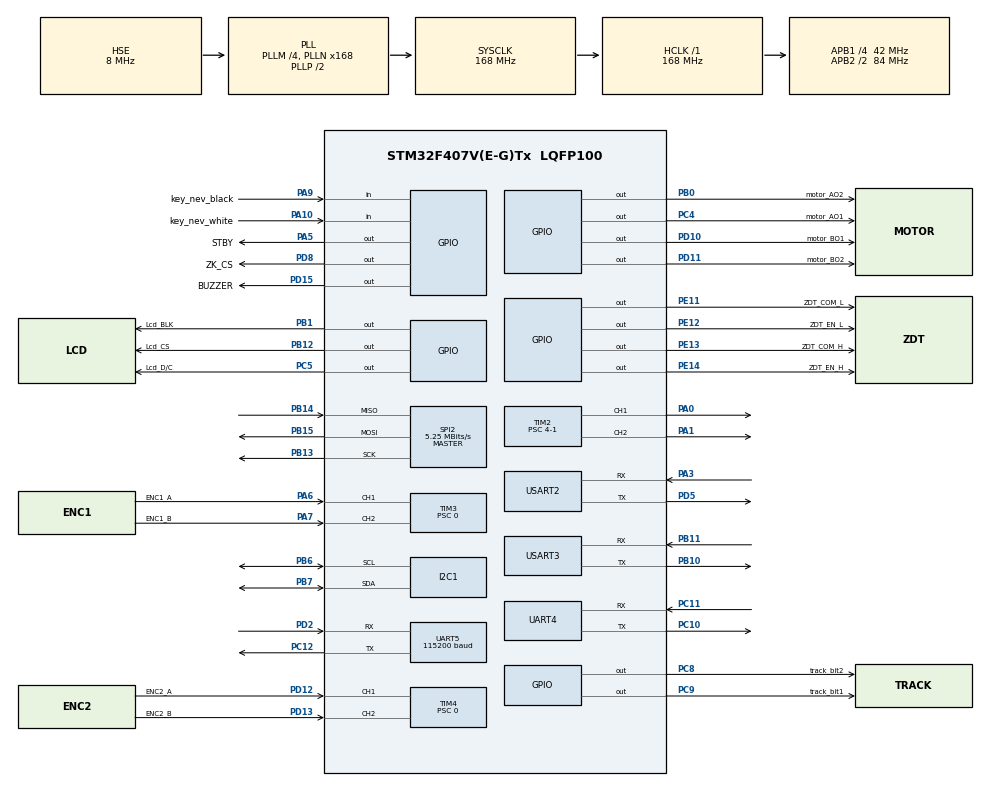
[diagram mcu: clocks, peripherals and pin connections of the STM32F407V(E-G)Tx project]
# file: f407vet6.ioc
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Dma.Request0=UART5_RX
Dma.Request1=USART2_RX
Dma.Request2=UART5_TX
Dma.UART5_RX.0.Direction=DMA_PERIPH_TO_MEMORY
Dma.UART5_RX.0.FIFOMode=DMA_FIFOMODE_DISABLE
Dma.UART5_RX.0.Instance=DMA1_Stream0
Dma.UART5_RX.0.MemDataAlignment=DMA_MDATAALIGN_BYTE
Dma.UART5_RX.0.MemInc=DMA_MINC_ENABLE
Dma.UART5_RX.0.Mode=DMA_NORMAL
Dma.UART5_RX.0.PeriphDataAlignment=DMA_PDATAALIGN_BYTE
Dma.UART5_RX.0.PeriphInc=DMA_PINC_DISABLE
Dma.UART5_RX.0.Priority=DMA_PRIORITY_MEDIUM
Dma.UART5_TX.2.Direction=DMA_MEMORY_TO_PERIPH
Dma.UART5_TX.2.FIFOMode=DMA_FIFOMODE_DISABLE
Dma.UART5_TX.2.Instance=DMA1_Stream7
Dma.UART5_TX.2.MemDataAlignment=DMA_MDATAALIGN_BYTE
Dma.UART5_TX.2.MemInc=DMA_MINC_ENABLE
Dma.UART5_TX.2.Mode=DMA_NORMAL
Dma.UART5_TX.2.PeriphDataAlignment=DMA_PDATAALIGN_BYTE
Dma.UART5_TX.2.PeriphInc=DMA_PINC_DISABLE
Dma.UART5_TX.2.Priority=DMA_PRIORITY_MEDIUM
Dma.USART2_RX.1.Direction=DMA_PERIPH_TO_MEMORY
Dma.USART2_RX.1.FIFOMode=DMA_FIFOMODE_DISABLE
Dma.USART2_RX.1.Instance=DMA1_Stream5
Dma.USART2_RX.1.MemDataAlignment=DMA_MDATAALIGN_BYTE
Dma.USART2_RX.1.MemInc=DMA_MINC_ENABLE
Dma.USART2_RX.1.Mode=DMA_NORMAL
Dma.USART2_RX.1.PeriphDataAlignment=DMA_PDATAALIGN_BYTE
Dma.USART2_RX.1.PeriphInc=DMA_PINC_DISABLE
Dma.USART2_RX.1.Priority=DMA_PRIORITY_MEDIUM
Mcu.Family=STM32F4
Mcu.Name=STM32F407V(E-G)Tx
Mcu.Package=LQFP100
NVIC.DMA1_Stream0_IRQn=true\:0\:0\:false\:false\:true\:false\:true\:true
NVIC.DMA1_Stream5_IRQn=true\:0\:0\:false\:false\:true\:false\:true\:true
NVIC.DMA1_Stream7_IRQn=true\:0\:0\:false\:false\:true\:false\:true\:true
NVIC.PriorityGroup=NVIC_PRIORITYGROUP_4
NVIC.UART5_IRQn=true\:0\:0\:false\:false\:true\:true\:true\:true
NVIC.USART2_IRQn=true\:0\:0\:false\:false\:true\:true\:true\:true
PA0-WKUP.Signal=S_TIM2_CH1_ETR
PA1.Signal=S_TIM2_CH2
PA10.GPIO_Label=key_nev_white
PA10.GPIO_PuPd=GPIO_PULLUP
PA10.Signal=GPIO_Input
PA13.Mode=Serial_Wire
PA13.Signal=SYS_JTMS-SWDIO
PA14.Mode=Serial_Wire
PA14.Signal=SYS_JTCK-SWCLK
PA3.Mode=Asynchronous
PA3.Signal=USART2_RX
PA5.GPIO_Label=STBY
PA5.Signal=GPIO_Output
PA6.GPIO_Label=ENC1_A
PA6.GPIO_PuPd=GPIO_PULLUP
PA6.GPIO_Speed=GPIO_SPEED_FREQ_MEDIUM
PA6.Signal=S_TIM3_CH1
PA7.GPIO_Label=ENC1_B
PA7.GPIO_PuPd=GPIO_PULLUP
PA7.GPIO_Speed=GPIO_SPEED_FREQ_MEDIUM
PA7.Signal=S_TIM3_CH2
PA9.GPIO_Label=key_nev_black
PA9.GPIO_PuPd=GPIO_PULLUP
PA9.Signal=GPIO_Input
PB0.GPIO_Label=motor_AO2
PB0.Signal=GPIO_Output
PB1.GPIO_Label=Lcd_BLK
PB1.Signal=GPIO_Output
PB10.Mode=Asynchronous
PB10.Signal=USART3_TX
PB11.Mode=Asynchronous
PB11.Signal=USART3_RX
PB12.GPIO_Label=Lcd_CS
PB12.Signal=GPIO_Output
PB13.Mode=Full_Duplex_Master
PB13.Signal=SPI2_SCK
PB14.Mode=Full_Duplex_Master
PB14.Signal=SPI2_MISO
PB15.Mode=Full_Duplex_Master
PB15.Signal=SPI2_MOSI
PB6.Mode=I2C
PB6.Signal=I2C1_SCL
PB7.Mode=I2C
PB7.Signal=I2C1_SDA
PC10.Mode=Asynchronous
PC10.Signal=UART4_TX
PC11.Mode=Asynchronous
PC11.Signal=UART4_RX
PC12.Mode=Asynchronous
PC12.Signal=UART5_TX
PC14-OSC32_IN.Mode=LSE-External-Oscillator
PC14-OSC32_IN.Signal=RCC_OSC32_IN
PC15-OSC32_OUT.Mode=LSE-External-Oscillator
PC15-OSC32_OUT.Signal=RCC_OSC32_OUT
PC4.GPIO_Label=motor_AO1
PC4.Signal=GPIO_Output
PC5.GPIO_Label=Lcd_D/C
PC5.Signal=GPIO_Output
PC8.GPIO_Label=track_bit2
PC8.Signal=GPIO_Output
PC9.GPIO_Label=track_bit1
PC9.Signal=GPIO_Output
PD10.GPIO_Label=motor_BO1
PD10.Signal=GPIO_Output
PD11.GPIO_Label=motor_BO2
PD11.Signal=GPIO_Output
PD12.GPIO_Label=ENC2_A
PD12.GPIO_PuPd=GPIO_PULLUP
PD12.GPIO_Speed=GPIO_SPEED_FREQ_MEDIUM
PD12.Signal=S_TIM4_CH1
PD13.GPIO_Label=ENC2_B
PD13.GPIO_PuPd=GPIO_PULLUP
PD13.GPIO_Speed=GPIO_SPEED_FREQ_MEDIUM
PD13.Signal=S_TIM4_CH2
PD15.GPIO_Label=BUZZER
PD15.Signal=GPIO_Output
PD2.Mode=Asynchronous
PD2.Signal=UART5_RX
PD5.Mode=Asynchronous
PD5.Signal=USART2_TX
PD8.GPIO_Label=ZK_CS
PD8.Signal=GPIO_Output
PE11.GPIO_Label=ZDT_COM_L
PE11.Signal=GPIO_Output
PE12.GPIO_Label=ZDT_EN_L
PE12.Signal=GPIO_Output
PE13.GPIO_Label=ZDT_COM_H
PE13.Signal=GPIO_Output
PE14.GPIO_Label=ZDT_EN_H
PE14.Signal=GPIO_Output
PH0-OSC_IN.Mode=HSE-External-Oscillator
PH0-OSC_IN.Signal=RCC_OSC_IN
PH1-OSC_OUT.Mode=HSE-External-Oscillator
PH1-OSC_OUT.Signal=RCC_OSC_OUT
ProjectManager.HeapSize=0x200
ProjectManager.StackSize=0x400
ProjectManager.TargetToolchain=MDK-ARM V5.32
RCC.48MHZClocksFreq_Value=84000000
RCC.AHBFreq_Value=168000000
RCC.APB1CLKDivider=RCC_HCLK_DIV4
RCC.APB1Freq_Value=42000000
RCC.APB1TimFreq_Value=84000000
RCC.APB2CLKDivider=RCC_HCLK_DIV2
RCC.APB2Freq_Value=84000000
RCC.APB2TimFreq_Value=168000000
RCC.CortexFreq_Value=168000000
RCC.HCLKFreq_Value=168000000
RCC.HSE_VALUE=8000000
RCC.HSI_VALUE=16000000
RCC.PLLM=4
RCC.PLLN=168
RCC.PLLSourceVirtual=RCC_PLLSOURCE_HSE
RCC.SYSCLKFreq_VALUE=168000000
RCC.SYSCLKSource=RCC_SYSCLKSOURCE_PLLCLK
RCC.VCOOutputFreq_Value=336000000
SH.S_TIM2_CH1_ETR.0=TIM2_CH1,PWM Generation1 CH1
SH.S_TIM2_CH2.0=TIM2_CH2,PWM Generation2 CH2
SH.S_TIM3_CH1.0=TIM3_CH1,Encoder_Interface
SH.S_TIM3_CH2.0=TIM3_CH2,Encoder_Interface
SH.S_TIM4_CH1.0=TIM4_CH1,Encoder_Interface
SH.S_TIM4_CH2.0=TIM4_CH2,Encoder_Interface
SPI2.BaudRatePrescaler=SPI_BAUDRATEPRESCALER_8
SPI2.CalculateBaudRate=5.25 MBits/s
SPI2.Direction=SPI_DIRECTION_2LINES
SPI2.Mode=SPI_MODE_MASTER
SPI2.VirtualType=VM_MASTER
TIM2.Channel-PWM\ Generation1\ CH1=TIM_CHANNEL_1
TIM2.Channel-PWM\ Generation2\ CH2=TIM_CHANNEL_2
TIM2.Period=1050-1
TIM2.Prescaler=4-1
TIM3.EncoderMode=TIM_ENCODERMODE_TI12
TIM3.IC1Filter=10
TIM3.IC2Filter=10
TIM3.Period=65535
TIM3.Prescaler=0
TIM4.EncoderMode=TIM_ENCODERMODE_TI12
TIM4.IC1Filter=10
TIM4.IC2Filter=10
TIM4.Period=65535
TIM4.Prescaler=0
UART4.VirtualMode=Asynchronous
UART5.BaudRate=115200
UART5.VirtualMode=Asynchronous
USART2.VirtualMode=VM_ASYNC
USART3.VirtualMode=VM_ASYNC
VP_TIM2_VS_ClockSourceINT.Mode=Internal
board=custom

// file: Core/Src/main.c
/* USER CODE BEGIN Header */
/**
  ******************************************************************************
  * @file           : main.c
  * @brief          : Main program body
  ******************************************************************************
  * @attention
  *
  * Copyright (c) 2026 STMicroelectronics.
  * All rights reserved.
  *
  * This software is licensed under terms that can be found in the LICENSE file
  * in the root directory of this software component.
  * If no LICENSE file comes with this software, it is provided AS-IS.
  *
  ******************************************************************************
  */
/* USER CODE END Header */
#include "main.h"
#include "dma.h"
#include "i2c.h"
#include "spi.h"
#include "tim.h"
#include "usart.h"
#include "gpio.h"

/* USER CODE BEGIN Includes */
#include "Myconfig.h"
/* USER CODE END Includes */

void SystemClock_Config(void);
/* USER CODE BEGIN PFP */
float t = 0;
  float data[4];
/* USER CODE END PFP */

int main(void)
{

  /* MCU Configuration--------------------------------------------------------*/

  /* Reset of all peripherals, Initializes the Flash interface and the Systick. */
  HAL_Init();

  /* Configure the system clock */
  SystemClock_Config();

  /* Initialize all configured peripherals */
  MX_GPIO_Init();
  MX_DMA_Init();
  MX_TIM2_Init();
  MX_TIM3_Init();
  MX_TIM4_Init();
  MX_SPI2_Init();
  MX_UART4_Init();
  MX_UART5_Init();
  MX_USART2_UART_Init();
  MX_USART3_UART_Init();
  MX_I2C1_Init();
  /* USER CODE BEGIN 2 */

  Scheduler_Init(); // 调度器初始化
  static uint8_t rx_byte;
  HAL_UART_Receive_IT(&huart3, &rx_byte, 1);
//  vJY901S_Data_Proc();
  /* USER CODE END 2 */

  /* Infinite loop */
  /* USER CODE BEGIN WHILE */

  while (1)
  {
      //int32_t steering = track_steering(my_track_sensor.Normal_value, 1);
//      t += 0.1;
//      data[0] = (float)(100*sin(t));
      Scheduler_Run();
//      unsigned char raw[8];
//  IIC_Get_Anolog(raw, 8);
//  printf("raw: %d,%d,%d,%d,%d,%d,%d,%d\r\n",
//         raw[0], raw[1], raw[2], raw[3],
//         raw[4], raw[5], raw[6], raw[7]);
//      track_task(&my_track_sensor);
//      printf("ADC: %d  %d  %d  %d  %d  %d  %d  %d\r\n Digtal: %d%d%d%d%d%d%d%d  ",
//      my_track_sensor.Analog_value[0], my_track_sensor.Analog_value[1],
//      my_track_sensor.Analog_value[2], my_track_sensor.Analog_value[3],
//      my_track_sensor.Analog_value[4], my_track_sensor.Analog_value[5],
//      my_track_sensor.Analog_value[6], my_track_sensor.Analog_value[7],
//      (my_track_sensor.Digtal >> 7) & 1, (my_track_sensor.Digtal >> 6) & 1,
//      (my_track_sensor.Digtal >> 5) & 1, (my_track_sensor.Digtal >> 4) & 1,
//      (my_track_sensor.Digtal >> 3) & 1, (my_track_sensor.Digtal >> 2) & 1,
//      (my_track_sensor.Digtal >> 1) & 1, (my_track_sensor.Digtal >> 0) & 1);
//     Data_send((int32_t)(left_speed_cm_s), (int32_t)left_pid.target,
//                (int32_t)(right_speed_cm_s), (int32_t)right_pid.target);
//  printf("Yaw: %d \r\n", jy901_Angle.Angle[2]);
//
    /* USER CODE END WHILE */

  }
}

void SystemClock_Config(void)
{
  RCC_OscInitTypeDef RCC_OscInitStruct = {0};
  RCC_ClkInitTypeDef RCC_ClkInitStruct = {0};

  /** Configure the main internal regulator output voltage
  */
  __HAL_RCC_PWR_CLK_ENABLE();
  __HAL_PWR_VOLTAGESCALING_CONFIG(PWR_REGULATOR_VOLTAGE_SCALE1);

  /** Initializes the RCC Oscillators according to the specified parameters
  * in the RCC_OscInitTypeDef structure.
  */
  RCC_OscInitStruct.OscillatorType = RCC_OSCILLATORTYPE_HSE;
  RCC_OscInitStruct.HSEState = RCC_HSE_ON;
  RCC_OscInitStruct.PLL.PLLState = RCC_PLL_ON;
  RCC_OscInitStruct.PLL.PLLSource = RCC_PLLSOURCE_HSE;
  RCC_OscInitStruct.PLL.PLLM = 4;
  RCC_OscInitStruct.PLL.PLLN = 168;
  RCC_OscInitStruct.PLL.PLLP = RCC_PLLP_DIV2;
  RCC_OscInitStruct.PLL.PLLQ = 4;
  if (HAL_RCC_OscConfig(&RCC_OscInitStruct) != HAL_OK)
  {
    Error_Handler();
  }

  /** Initializes the CPU, AHB and APB buses clocks
  */
  RCC_ClkInitStruct.ClockType = RCC_CLOCKTYPE_HCLK|RCC_CLOCKTYPE_SYSCLK
                              |RCC_CLOCKTYPE_PCLK1|RCC_CLOCKTYPE_PCLK2;
  RCC_ClkInitStruct.SYSCLKSource = RCC_SYSCLKSOURCE_PLLCLK;
  RCC_ClkInitStruct.AHBCLKDivider = RCC_SYSCLK_DIV1;
  RCC_ClkInitStruct.APB1CLKDivider = RCC_HCLK_DIV4;
  RCC_ClkInitStruct.APB2CLKDivider = RCC_HCLK_DIV2;

  if (HAL_RCC_ClockConfig(&RCC_ClkInitStruct, FLASH_LATENCY_5) != HAL_OK)
  {
    Error_Handler();
  }
}

void Error_Handler(void)
{
  __disable_irq();
  while (1)
  {
  }
}
